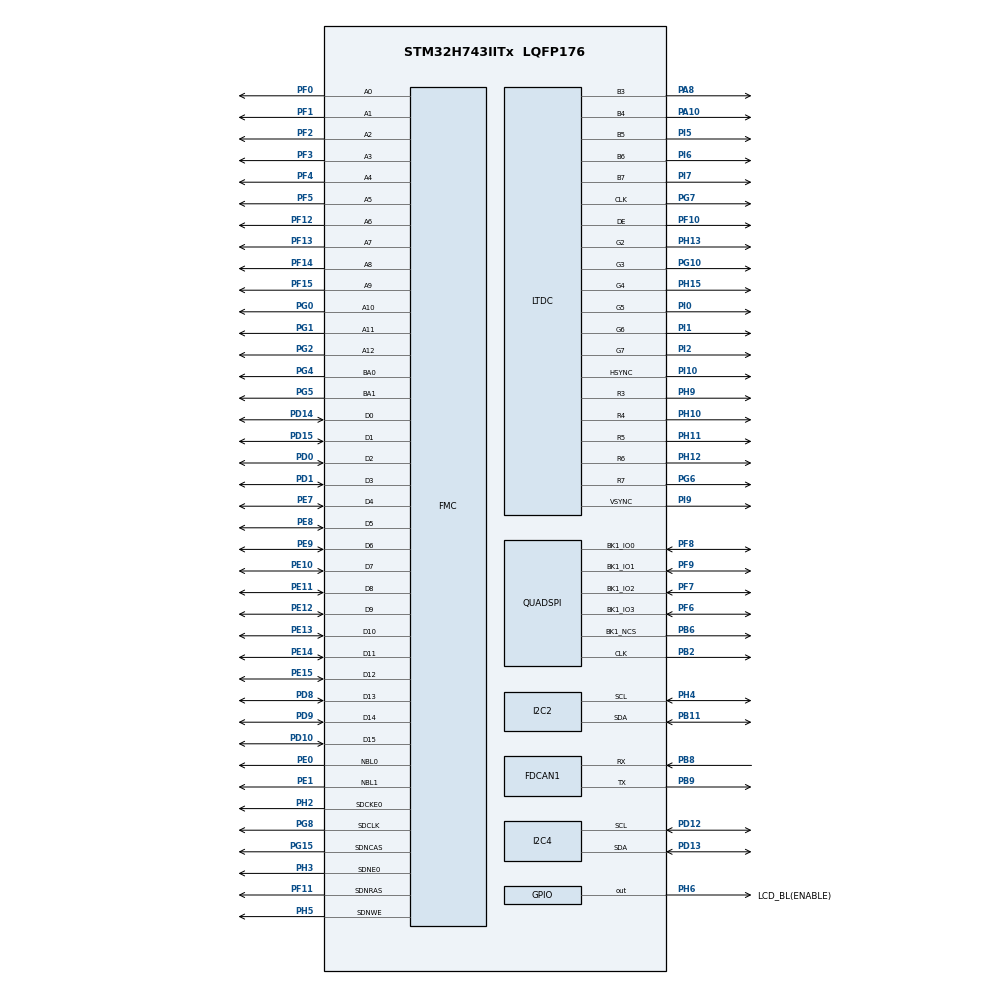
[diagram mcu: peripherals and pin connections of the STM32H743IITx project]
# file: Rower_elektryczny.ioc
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CORTEX_M7.default_mode_Activation=1
FDCAN1.AutoRetransmission=ENABLE
FDCAN1.CalculateBaudRateNominal=500000
FDCAN1.CalculateTimeBitNominal=2000
FDCAN1.CalculateTimeQuantumNominal=80.0
FDCAN1.ClockCalibrationCCU=DISABLE
FDCAN1.DataPrescaler=2
FDCAN1.DataSyncJumpWidth=12
FDCAN1.DataTimeSeg1=12
FDCAN1.DataTimeSeg2=7
FDCAN1.ExtFiltersNbr=5
FDCAN1.Mode=FDCAN_MODE_NORMAL
FDCAN1.NominalPrescaler=2
FDCAN1.NominalSyncJumpWidth=7
FDCAN1.NominalTimeSeg1=17
FDCAN1.NominalTimeSeg2=7
FDCAN1.RxFifo0ElmtsNbr=5
FDCAN1.StdFiltersNbr=5
FDCAN1.TxFifoQueueElmtsNbr=3
FMC.CASLatency1=FMC_SDRAM_CAS_LATENCY_3
FMC.ColumnBitsNumber1=FMC_SDRAM_COLUMN_BITS_NUM_9
FMC.ExitSelfRefreshDelay1=7
FMC.LoadToActiveDelay1=2
FMC.RCDDelay1=2
FMC.RPDelay1=2
FMC.RPDelay2=2
FMC.ReadPipeDelay1=FMC_SDRAM_RPIPE_DELAY_1
FMC.ReadPipeDelay2=FMC_SDRAM_RPIPE_DELAY_1
FMC.RowCycleDelay1=7
FMC.RowCycleDelay2=7
FMC.SDClockPeriod1=FMC_SDRAM_CLOCK_PERIOD_2
FMC.SDClockPeriod2=FMC_SDRAM_CLOCK_PERIOD_2
FMC.SelfRefreshTime1=4
FMC.WriteRecoveryTime1=3
I2C2.Timing=0x00000E14
I2C4.Timing=0x00000E14
LTDC.Alpha_L0=255
LTDC.Alpha_L1=255
LTDC.FBStartAdress_L0=0xc0000000
LTDC.ImageHeight_L0=600
LTDC.ImageWidth_L0=1024
LTDC.Layers=0
LTDC.PixelFormat_L0=LTDC_PIXEL_FORMAT_RGB565
LTDC.WindowX1_L0=1024
LTDC.WindowX1_L1=1024
LTDC.WindowY1_L0=600
LTDC.WindowY1_L1=600
Mcu.Family=STM32H7
Mcu.Name=STM32H743IITx
Mcu.Package=LQFP176
NVIC.FDCAN1_IT0_IRQn=true\:0\:0\:false\:false\:true\:true\:true\:true
NVIC.FDCAN1_IT1_IRQn=true\:0\:0\:false\:false\:true\:true\:true\:true
NVIC.FDCAN_CAL_IRQn=true\:0\:0\:false\:false\:true\:true\:true\:true
NVIC.FMC_IRQn=true\:0\:0\:false\:false\:true\:true\:true\:true
NVIC.PriorityGroup=NVIC_PRIORITYGROUP_4
PA10.Mode=RGB565
PA10.Signal=LTDC_B4
PA13\ (JTMS/SWDIO).Mode=Serial_Wire
PA13\ (JTMS/SWDIO).Signal=DEBUG_JTMS-SWDIO
PA14\ (JTCK/SWCLK).Mode=Serial_Wire
PA14\ (JTCK/SWCLK).Signal=DEBUG_JTCK-SWCLK
PA8.Mode=RGB565
PA8.Signal=LTDC_B3
PB11.Mode=I2C
PB11.Signal=I2C2_SDA
PB2.Mode=Single Bank 1
PB2.Signal=QUADSPI_CLK
PB3\ (JTDO/TRACESWO).Signal=SDMMC2_D2
PB6.Mode=Single Bank 1
PB6.Signal=QUADSPI_BK1_NCS
PB8.Mode=FDCAN_Activate
PB8.Signal=FDCAN1_RX
PB9.Mode=FDCAN_Activate
PB9.Signal=FDCAN1_TX
PC14-OSC32_IN\ (OSC32_IN).Mode=LSE-External-Oscillator
PC14-OSC32_IN\ (OSC32_IN).Signal=RCC_OSC32_IN
PC15-OSC32_OUT\ (OSC32_OUT).Mode=LSE-External-Oscillator
PC15-OSC32_OUT\ (OSC32_OUT).Signal=RCC_OSC32_OUT
PD0.Signal=FMC_D2_DA2
PD1.Signal=FMC_D3_DA3
PD10.Signal=FMC_D15_DA15
PD12.Mode=I2C
PD12.Signal=I2C4_SCL
PD13.Mode=I2C
PD13.Signal=I2C4_SDA
PD14.Signal=FMC_D0_DA0
PD15.Signal=FMC_D1_DA1
PD7.Signal=SDMMC2_CMD
PD8.Signal=FMC_D13_DA13
PD9.Signal=FMC_D14_DA14
PE0.Signal=FMC_NBL0
PE1.Signal=FMC_NBL1
PE10.Signal=FMC_D7_DA7
PE11.Signal=FMC_D8_DA8
PE12.Signal=FMC_D9_DA9
PE13.Signal=FMC_D10_DA10
PE14.Signal=FMC_D11_DA11
PE15.Signal=FMC_D12_DA12
PE7.Signal=FMC_D4_DA4
PE8.Signal=FMC_D5_DA5
PE9.Signal=FMC_D6_DA6
PF0.Signal=FMC_A0
PF1.Signal=FMC_A1
PF10.Mode=RGB565
PF10.Signal=LTDC_DE
PF11.Signal=FMC_SDNRAS
PF12.Signal=FMC_A6
PF13.Signal=FMC_A7
PF14.Signal=FMC_A8
PF15.Signal=FMC_A9
PF2.Signal=FMC_A2
PF3.Signal=FMC_A3
PF4.Signal=FMC_A4
PF5.Signal=FMC_A5
PF6.Mode=Single Bank 1
PF6.Signal=QUADSPI_BK1_IO3
PF7.Mode=Single Bank 1
PF7.Signal=QUADSPI_BK1_IO2
PF8.Mode=Single Bank 1
PF8.Signal=QUADSPI_BK1_IO0
PF9.Mode=Single Bank 1
PF9.Signal=QUADSPI_BK1_IO1
PG0.Signal=FMC_A10
PG1.Signal=FMC_A11
PG10.Mode=RGB565
PG10.Signal=LTDC_G3
PG15.Signal=FMC_SDNCAS
PG2.Signal=FMC_A12
PG4.Signal=FMC_A14_BA0
PG5.Signal=FMC_A15_BA1
PG6.Mode=RGB565
PG6.Signal=LTDC_R7
PG7.Mode=RGB565
PG7.Signal=LTDC_CLK
PG8.Signal=FMC_SDCLK
PH0-OSC_IN\ (PH0).Mode=HSE-External-Oscillator
PH0-OSC_IN\ (PH0).Signal=RCC_OSC_IN
PH1-OSC_OUT\ (PH1).Mode=HSE-External-Oscillator
PH1-OSC_OUT\ (PH1).Signal=RCC_OSC_OUT
PH10.Mode=RGB565
PH10.Signal=LTDC_R4
PH11.Mode=RGB565
PH11.Signal=LTDC_R5
PH12.Mode=RGB565
PH12.Signal=LTDC_R6
PH13.Mode=RGB565
PH13.Signal=LTDC_G2
PH15.Mode=RGB565
PH15.Signal=LTDC_G4
PH2.Mode=SdramChipSelect1_1
PH2.Signal=FMC_SDCKE0
PH3.Mode=SdramChipSelect1_1
PH3.Signal=FMC_SDNE0
PH4.Mode=I2C
PH4.Signal=I2C2_SCL
PH5.Signal=FMC_SDNWE
PH6.GPIO_Label=LCD_BL(ENABLE)
PH6.Signal=GPIO_Output
PH9.Mode=RGB565
PH9.Signal=LTDC_R3
PI0.Mode=RGB565
PI0.Signal=LTDC_G5
PI1.Mode=RGB565
PI1.Signal=LTDC_G6
PI10.Mode=RGB565
PI10.Signal=LTDC_HSYNC
PI2.Mode=RGB565
PI2.Signal=LTDC_G7
PI5.Mode=RGB565
PI5.Signal=LTDC_B5
PI6.Mode=RGB565
PI6.Signal=LTDC_B6
PI7.Mode=RGB565
PI7.Signal=LTDC_B7
PI9.Mode=RGB565
PI9.Signal=LTDC_VSYNC
ProjectManager.HeapSize=0x200
ProjectManager.StackSize=0x400
ProjectManager.TargetToolchain=STM32CubeIDE
RCC.ADCFreq_Value=129000000
RCC.APB1Freq_Value=64000000
RCC.APB2Freq_Value=64000000
RCC.APB3Freq_Value=64000000
RCC.APB4Freq_Value=64000000
RCC.CortexFreq_Value=64000000
RCC.DIVM1=4
RCC.DIVM3=1
RCC.DIVN1=10
RCC.DIVN3=4
RCC.DIVQ1=3
RCC.DIVR3=6
RCC.FDCANCLockSelection=RCC_FDCANCLKSOURCE_HSE
RCC.HCLKFreq_Value=64000000
RCC.I2C123CLockSelection=RCC_I2C123CLKSOURCE_CSI
RCC.I2C4CLockSelection=RCC_I2C4CLKSOURCE_CSI
RCC.PLL2FRACN=0
RCC.PLL3FRACN=0
RCC.PLLFRACN=0
RCC.SYSCLKFreq_VALUE=64000000
RCC.USBFreq_Value=53333333.333333336
SH.FMC_A0.0=FMC_A0,13b-sda1
SH.FMC_A1.0=FMC_A1,13b-sda1
SH.FMC_A10.0=FMC_A10,13b-sda1
SH.FMC_A11.0=FMC_A11,13b-sda1
SH.FMC_A12.0=FMC_A12,13b-sda1
SH.FMC_A14_BA0.0=FMC_BA0,FourSdramBanks1
SH.FMC_A15_BA1.0=FMC_BA1,FourSdramBanks1
SH.FMC_A2.0=FMC_A2,13b-sda1
SH.FMC_A3.0=FMC_A3,13b-sda1
SH.FMC_A4.0=FMC_A4,13b-sda1
SH.FMC_A5.0=FMC_A5,13b-sda1
SH.FMC_A6.0=FMC_A6,13b-sda1
SH.FMC_A7.0=FMC_A7,13b-sda1
SH.FMC_A8.0=FMC_A8,13b-sda1
SH.FMC_A9.0=FMC_A9,13b-sda1
SH.FMC_D0_DA0.0=FMC_D0,sd-16b-d1
SH.FMC_D10_DA10.0=FMC_D10,sd-16b-d1
SH.FMC_D11_DA11.0=FMC_D11,sd-16b-d1
SH.FMC_D12_DA12.0=FMC_D12,sd-16b-d1
SH.FMC_D13_DA13.0=FMC_D13,sd-16b-d1
SH.FMC_D14_DA14.0=FMC_D14,sd-16b-d1
SH.FMC_D15_DA15.0=FMC_D15,sd-16b-d1
SH.FMC_D1_DA1.0=FMC_D1,sd-16b-d1
SH.FMC_D2_DA2.0=FMC_D2,sd-16b-d1
SH.FMC_D3_DA3.0=FMC_D3,sd-16b-d1
SH.FMC_D4_DA4.0=FMC_D4,sd-16b-d1
SH.FMC_D5_DA5.0=FMC_D5,sd-16b-d1
SH.FMC_D6_DA6.0=FMC_D6,sd-16b-d1
SH.FMC_D7_DA7.0=FMC_D7,sd-16b-d1
SH.FMC_D8_DA8.0=FMC_D8,sd-16b-d1
SH.FMC_D9_DA9.0=FMC_D9,sd-16b-d1
SH.FMC_NBL0.0=FMC_NBL0,Sd2ByteEnable1
SH.FMC_NBL1.0=FMC_NBL1,Sd2ByteEnable1
SH.FMC_SDCLK.0=FMC_SDCLK,13b-sda1
SH.FMC_SDNCAS.0=FMC_SDNCAS,13b-sda1
SH.FMC_SDNRAS.0=FMC_SDNRAS,13b-sda1
SH.FMC_SDNWE.0=FMC_SDNWE,13b-sda1
VP_CRC_VS_CRC.Mode=CRC_Activate
VP_DMA2D_VS_DMA2D.Mode=DMA2D_Activate
VP_MEMORYMAP_VS_MEMORYMAP.Mode=CurAppReg
VP_RCC_LSE.Mode=CRS SYNC Source LSE
board=custom

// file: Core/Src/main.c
/* USER CODE BEGIN Header */
/**
  ******************************************************************************
  * @file           : main.c
  * @brief          : Main program body
  ******************************************************************************
  * @attention
  *
  * Copyright (c) 2025 STMicroelectronics.
  * All rights reserved.
  *
  * This software is licensed under terms that can be found in the LICENSE file
  * in the root directory of this software component.
  * If no LICENSE file comes with this software, it is provided AS-IS.
  *
  ******************************************************************************
  */
/* USER CODE END Header */
#include "main.h"
#include "crc.h"
#include "dma2d.h"
#include "fdcan.h"
#include "i2c.h"
#include "ltdc.h"
#include "memorymap.h"
#include "quadspi.h"
#include "gpio.h"
#include "fmc.h"

/* USER CODE BEGIN PV */
FDCAN_RxHeaderTypeDef RxHeader;
uint8_t RxData[8]; // Bufor na dane odebrane z VESC
uint8_t TxData[8]; // Bufor na dane do wysłania
// --- 1. DEFINICJA STRUKTURY DLA WSZYSTKICH STATUSÓW ---
FDCAN_TxHeaderTypeDef TxHeader;
typedef struct {
    // === STATUS 1 (Komenda 0x09) ===
    volatile int32_t rpm;           // Prędkość obrotowa (ERPM)
    volatile float current_motor;   // Prąd na silniku (A)
    volatile float duty_cycle;      // Wypełnienie (0.00 - 1.00)

    // === STATUS 2 (Komenda 0x0E) ===
    volatile float amp_hours;       // Zużyte amperogodziny (Ah)
    volatile float amp_hours_chg;   // Odzyskane amperogodziny (ładowanie)

    // === STATUS 3 (Komenda 0x0F) ===
    volatile float watt_hours;      // Zużyte watogodziny (Wh)
    volatile float watt_hours_chg;  // Odzyskane watogodziny (ładowanie)

    // === STATUS 4 (Komenda 0x10) ===
    volatile float temp_fet;        // Temperatura MOSFET-ów (st. C)
    volatile float temp_motor;      // Temperatura Silnika (st. C)
    volatile float current_in;      // Prąd pobierany z baterii (A)
    volatile float pid_pos;         // Pozycja PID (kąt 0-360)

    // === STATUS 5 (Komenda 0x1B) ===
    volatile int32_t tacho_value;   // Licznik obrotów (przebieg)
    volatile float v_in;            // Napięcie baterii (V)

} VescData_t;

// --- 2. INSTANCJE DLA SILNIKÓW ---
// Ustawiamy ID Twoich VESC-ów
#define VESC_ID_L  1   // Lewy
#define VESC_ID_M  2   // Środkowy
#define VESC_ID_R  3   // Prawy (przykładowo)

VescData_t vescL; // Zmienna dla lewego
VescData_t vescM; // Zmienna dla środkowego
VescData_t vescR; // Zmienna dla prawego

// --- MPU6050 DEFINICJE ---
#define MPU6050_ADDR 0xD0 // Adres urządzenia (0x68 << 1)
#define SMPLRT_DIV_REG 0x19
#define GYRO_CONFIG_REG 0x1B
#define ACCEL_CONFIG_REG 0x1C
#define ACCEL_XOUT_H_REG 0x3B
#define TEMP_OUT_H_REG 0x41
#define GYRO_XOUT_H_REG 0x43
#define PWR_MGMT_1_REG 0x6B
#define WHO_AM_I_REG 0x75

// Struktura przechowująca dane z czujnika
typedef struct {
    int16_t Accel_X_RAW;
    int16_t Accel_Y_RAW;
    int16_t Accel_Z_RAW;
    double Ax; // Przyspieszenie w g
    double Ay;
    double Az;

    int16_t Gyro_X_RAW;
    int16_t Gyro_Y_RAW;
    int16_t Gyro_Z_RAW;
    double Gx; // Prędkość kątowa w deg/s
    double Gy;
    double Gz;

    float Temperature;
} MPU6050_t;

MPU6050_t MPU6050; // Globalna instancja struktury

/* USER CODE END PV */

void SystemClock_Config(void);
static void MPU_Config(void);

/* USER CODE BEGIN PFP */
void VESC_SetDuty(uint8_t controller_id, float dutyCycle);
void VESC_SetAllDuty(float duty_Left, float duty_Right, float duty_Gen);

uint8_t MPU6050_Init(I2C_HandleTypeDef *I2Cx);
void MPU6050_Read_All(I2C_HandleTypeDef *I2Cx, MPU6050_t *DataStruct);
/* USER CODE END PFP */

int main(void)
{

  /* MPU Configuration--------------------------------------------------------*/
  MPU_Config();

  /* MCU Configuration--------------------------------------------------------*/

  /* Reset of all peripherals, Initializes the Flash interface and the Systick. */
  HAL_Init();

  /* Configure the system clock */
  SystemClock_Config();

  /* Initialize all configured peripherals */
  MX_GPIO_Init();
  MX_FMC_Init();
  MX_QUADSPI_Init();
  MX_LTDC_Init();
  MX_DMA2D_Init();
  MX_FDCAN1_Init();
  MX_I2C4_Init();
  MX_I2C2_Init();
  MX_CRC_Init();
  /* USER CODE BEGIN 2 */
  // 1. Konfiguracja Filtra - akceptujemy WSZYSTKO (tryb otwarty dla testów)
    // VESC wysyła ramki z ID rozszerzonym (29-bit).
    FDCAN_FilterTypeDef sFilterConfig;

    sFilterConfig.IdType = FDCAN_EXTENDED_ID;
    sFilterConfig.FilterIndex = 0;
    sFilterConfig.FilterType = FDCAN_FILTER_MASK;
    sFilterConfig.FilterConfig = FDCAN_FILTER_TO_RXFIFO0;
    sFilterConfig.FilterID1 = 0;     // Akceptuj wszystko
    sFilterConfig.FilterID2 = 0;     // Maska 0 = ignoruj bity ID (bierz wszystko jak leci)

    if (HAL_FDCAN_ConfigFilter(&hfdcan1, &sFilterConfig) != HAL_OK)
    {
      Error_Handler();
    }

    // 2. Start modułu FDCAN
    if (HAL_FDCAN_Start(&hfdcan1) != HAL_OK)
    {
      Error_Handler();
    }

    // 3. Włączenie przerwań (chcemy wiedzieć, kiedy przyjdzie nowa wiadomość)
    if (HAL_FDCAN_ActivateNotification(&hfdcan1, FDCAN_IT_RX_FIFO0_NEW_MESSAGE, 0) != HAL_OK)
    {
      Error_Handler();
    }
    if (MPU6050_Init(&hi2c2) == 0) {
          // Opcjonalnie: mignij diodą, że MPU OK
      }
  /* USER CODE END 2 */

  /* Infinite loop */
  /* USER CODE BEGIN WHILE */
    // Zmienna do filtra (musi być static, żeby pamiętała wartość z poprzedniego obiegu)
      static float current_filtered = 0.0f;

      // Konfiguracja Twojej krzywej
      const float MAX_GEN_RPM = 10000.0f; // Przy jakich obrotach chcesz miec PEŁNĄ MOC (zwiększ jeśli 8000 to za mało)
      const float MAX_CURRENT = 20.0f;    // Maksymalny prąd w Amperach
      const float RAMP_FACTOR = 0.05f;    // Jak szybko prąd ma gonić cel (0.01 = bardzo wolno/płynnie, 0.1 = szybko)

  while (1)
  {
    /* USER CODE END WHILE */

    /* USER CODE BEGIN 3 */
	  MPU6050_Read_All(&hi2c2, &MPU6050);
	  // 1. Pobierz obroty
	      int32_t rpm_raw = vescM.rpm;
	      if (rpm_raw < 0) rpm_raw = 0; // Zabezpieczenie przed ujemnymi

	      // 2. Martwa strefa (np. do 200 erpm nic nie rób, żeby silnik nie buczał na postoju)
	      if (rpm_raw < 200) rpm_raw = 0;

	      // --- MAGIA MATEMATYKI (Krzywa Kwadratowa) ---

	      // A. Obliczamy w jakim % drogi do maksa jesteśmy (0.0 do 1.0)
	      float throttle_pos = (float)rpm_raw / MAX_GEN_RPM;
	      if (throttle_pos > 1.0f) throttle_pos = 1.0f; // Nie przekraczaj 100%

	      // B. Podnosimy do kwadratu -> To daje łagodny start!
	      // Przykład:
	      // Liniowo: 50% RPM = 50% Prądu
	      // Kwadratowo: 0.5 * 0.5 = 0.25 (czyli przy połowie obrotów masz tylko 25% mocy!)
	      float current_target = throttle_pos * throttle_pos * MAX_CURRENT;

	      // --- FILTROWANIE (RAMPING) ---
	      // To realizuje Twoją prośbę o "mniejsze przyrosty".
	      // Prąd nie skacze od razu do celu, tylko zbliża się o 5% różnicy w każdym kroku pętli.
	      current_filtered = (current_filtered * (1.0f - RAMP_FACTOR)) + (current_target * RAMP_FACTOR);

	      // Zabezpieczenie "na wszelki wypadek"
	      if (current_filtered < 0.1f) current_filtered = 0.0f; // Zeruj małe śmieci

	      // 3. Wyślij wygładzony, "miękki" prąd na silniki
	      VESC_SetCurrent(VESC_ID_L, current_filtered);

	      // Krótkie opóźnienie dla stabilności CAN (ważne przy 3 VESC)
	      HAL_Delay(1);

	      VESC_SetCurrent(VESC_ID_R, current_filtered);

	      // Częstotliwość pętli (ok 50Hz)
	      HAL_Delay(20);
  }
  /* USER CODE END 3 */
}

void SystemClock_Config(void)
{
  RCC_OscInitTypeDef RCC_OscInitStruct = {0};
  RCC_ClkInitTypeDef RCC_ClkInitStruct = {0};
  RCC_CRSInitTypeDef RCC_CRSInitStruct = {0};

  /** Supply configuration update enable
  */
  HAL_PWREx_ConfigSupply(PWR_LDO_SUPPLY);

  /** Configure the main internal regulator output voltage
  */
  __HAL_PWR_VOLTAGESCALING_CONFIG(PWR_REGULATOR_VOLTAGE_SCALE3);

  while(!__HAL_PWR_GET_FLAG(PWR_FLAG_VOSRDY)) {}

  /** Configure LSE Drive Capability
  */
  HAL_PWR_EnableBkUpAccess();
  __HAL_RCC_LSEDRIVE_CONFIG(RCC_LSEDRIVE_LOW);

  /** Macro to configure the PLL clock source
  */
  __HAL_RCC_PLL_PLLSOURCE_CONFIG(RCC_PLLSOURCE_HSI);

  /** Initializes the RCC Oscillators according to the specified parameters
  * in the RCC_OscInitTypeDef structure.
  */
  RCC_OscInitStruct.OscillatorType = RCC_OSCILLATORTYPE_HSI48|RCC_OSCILLATORTYPE_CSI
                              |RCC_OSCILLATORTYPE_HSI|RCC_OSCILLATORTYPE_HSE
                              |RCC_OSCILLATORTYPE_LSE;
  RCC_OscInitStruct.HSEState = RCC_HSE_ON;
  RCC_OscInitStruct.LSEState = RCC_LSE_ON;
  RCC_OscInitStruct.HSIState = RCC_HSI_DIV1;
  RCC_OscInitStruct.HSICalibrationValue = RCC_HSICALIBRATION_DEFAULT;
  RCC_OscInitStruct.HSI48State = RCC_HSI48_ON;
  RCC_OscInitStruct.CSIState = RCC_CSI_ON;
  RCC_OscInitStruct.CSICalibrationValue = RCC_CSICALIBRATION_DEFAULT;
  RCC_OscInitStruct.PLL.PLLState = RCC_PLL_NONE;
  if (HAL_RCC_OscConfig(&RCC_OscInitStruct) != HAL_OK)
  {
    Error_Handler();
  }

  /** Initializes the CPU, AHB and APB buses clocks
  */
  RCC_ClkInitStruct.ClockType = RCC_CLOCKTYPE_HCLK|RCC_CLOCKTYPE_SYSCLK
                              |RCC_CLOCKTYPE_PCLK1|RCC_CLOCKTYPE_PCLK2
                              |RCC_CLOCKTYPE_D3PCLK1|RCC_CLOCKTYPE_D1PCLK1;
  RCC_ClkInitStruct.SYSCLKSource = RCC_SYSCLKSOURCE_HSI;
  RCC_ClkInitStruct.SYSCLKDivider = RCC_SYSCLK_DIV1;
  RCC_ClkInitStruct.AHBCLKDivider = RCC_HCLK_DIV1;
  RCC_ClkInitStruct.APB3CLKDivider = RCC_APB3_DIV1;
  RCC_ClkInitStruct.APB1CLKDivider = RCC_APB1_DIV1;
  RCC_ClkInitStruct.APB2CLKDivider = RCC_APB2_DIV1;
  RCC_ClkInitStruct.APB4CLKDivider = RCC_APB4_DIV1;

  if (HAL_RCC_ClockConfig(&RCC_ClkInitStruct, FLASH_LATENCY_1) != HAL_OK)
  {
    Error_Handler();
  }

  /** Enable the SYSCFG APB clock
  */
  __HAL_RCC_CRS_CLK_ENABLE();

  /** Configures CRS
  */
  RCC_CRSInitStruct.Prescaler = RCC_CRS_SYNC_DIV1;
  RCC_CRSInitStruct.Source = RCC_CRS_SYNC_SOURCE_LSE;
  RCC_CRSInitStruct.Polarity = RCC_CRS_SYNC_POLARITY_RISING;
  RCC_CRSInitStruct.ReloadValue = __HAL_RCC_CRS_RELOADVALUE_CALCULATE(48000000,32768);
  RCC_CRSInitStruct.ErrorLimitValue = 34;
  RCC_CRSInitStruct.HSI48CalibrationValue = 32;

  HAL_RCCEx_CRSConfig(&RCC_CRSInitStruct);
}

/* USER CODE BEGIN 4 */
void HAL_FDCAN_RxFifo0Callback(FDCAN_HandleTypeDef *hfdcan, uint32_t RxFifo0ITs)
{
    // Czy przyszła nowa wiadomość?
    if ((RxFifo0ITs & FDCAN_IT_RX_FIFO0_NEW_MESSAGE) != 0)
    {
        // Pobierz wiadomość
        if (HAL_FDCAN_GetRxMessage(hfdcan, FDCAN_RX_FIFO0, &RxHeader, RxData) == HAL_OK)
        {
            // 1. Rozpoznanie KTO wysłał (ID VESC)
            uint8_t id_nadawcy = (RxHeader.Identifier & 0xFF);

            // 2. Rozpoznanie CO wysłał (Komenda)
            uint8_t komenda = (RxHeader.Identifier >> 8) & 0xFF;

            // 3. Wybór odpowiedniej struktury (Wskaźnik)
            VescData_t *target = NULL;

            if      (id_nadawcy == VESC_ID_M) target = &vescM; // Środkowy
            else if (id_nadawcy == VESC_ID_L) target = &vescL; // Lewy
            else if (id_nadawcy == VESC_ID_R) target = &vescR; // Prawy

            // Jeśli znaleźliśmy pasujący silnik, dekodujemy dane
            if (target != NULL)
            {
                switch (komenda)
                {
                    // --- STATUS 1: RPM, Prąd Silnika, Duty ---
                    case 0x09:
                        target->rpm = (int32_t)((RxData[0] << 24) | (RxData[1] << 16) | (RxData[2] << 8) | RxData[3]);
                        target->current_motor = (float)((int16_t)((RxData[4] << 8) | RxData[5])) / 10.0f;
                        target->duty_cycle = (float)((int16_t)((RxData[6] << 8) | RxData[7])) / 1000.0f;
                        break;

                        // --- STATUS 2: Ah zużyte, Ah odzyskane ---
                        case 0x0E:
                            target->amp_hours = (float)((int32_t)((RxData[0] << 24) | (RxData[1] << 16) | (RxData[2] << 8) | RxData[3])) / 10000.0f;
                            // POPRAWKA PONIŻEJ: 24, 16, 8, 0
                            target->amp_hours_chg = (float)((int32_t)((RxData[4] << 24) | (RxData[5] << 16) | (RxData[6] << 8) | RxData[7])) / 10000.0f;
                            break;

                        // --- STATUS 3: Wh zużyte, Wh odzyskane ---
                        case 0x0F:
                             target->watt_hours = (float)((int32_t)((RxData[0] << 24) | (RxData[1] << 16) | (RxData[2] << 8) | RxData[3])) / 10000.0f;
                             // POPRAWKA PONIŻEJ: 24, 16, 8, 0
                             target->watt_hours_chg = (float)((int32_t)((RxData[4] << 24) | (RxData[5] << 16) | (RxData[6] << 8) | RxData[7])) / 10000.0f;
                            break;

                    // --- STATUS 4: Temperatury, Prąd Baterii ---
                    case 0x10:
                        target->temp_fet = (float)((int16_t)((RxData[0] << 8) | RxData[1])) / 10.0f;
                        target->temp_motor = (float)((int16_t)((RxData[2] << 8) | RxData[3])) / 10.0f;
                        target->current_in = (float)((int16_t)((RxData[4] << 8) | RxData[5])) / 10.0f;
                        target->pid_pos = (float)((int16_t)((RxData[6] << 8) | RxData[7])) / 50.0f;
                        break;

                    // --- STATUS 5: Tachometr, Napięcie Baterii ---
                    case 0x1B:
                        target->tacho_value = (int32_t)((RxData[0] << 24) | (RxData[1] << 16) | (RxData[2] << 8) | RxData[3]);
                        target->v_in = (float)((int16_t)((RxData[4] << 8) | RxData[5])) / 10.0f;
                        break;

                    default:
                        break;
                }
            }
        }
        // Ponowne włączenie nasłuchiwania
        HAL_FDCAN_ActivateNotification(hfdcan, FDCAN_IT_RX_FIFO0_NEW_MESSAGE, 0);
    }
}

// --- Funkcja ustawiania PRĄDU (Momentu) ---
// Komenda 0x01 w VESC to Set Current
void VESC_SetCurrent(uint8_t controller_id, float current_amps)
{
    // 1. Zabezpieczenie przed ujemnym prądem (chyba że chcesz hamować/wsteczny)
    // Zakładamy, że rower jedzie tylko do przodu.
    if (current_amps < 0.0f) current_amps = 0.0f;

    // 2. Zabezpieczenie maksymalnego prądu (bezpiecznik programowy)
    // Z tabelki wynika max 20A, ale dajmy bezpiecznik np. 30A
    if (current_amps > 30.0f) current_amps = 30.0f;

    // 3. Skalowanie: VESC oczekuje prądu * 1000 (miliampery)
    int32_t send_val = (int32_t)(current_amps * 1000.0f);

    FDCAN_TxHeaderTypeDef TxHeader;
    uint8_t TxData[4];

    // Budowa ID ramki: [KOMENDA 0x01] [ID_STEROWNIKA]
    TxHeader.Identifier = (uint32_t)controller_id | ((uint32_t)0x01 << 8);

    // Konfiguracja FDCAN (identyczna jak w działającym SetDuty)
    TxHeader.IdType = FDCAN_EXTENDED_ID;
    TxHeader.TxFrameType = FDCAN_DATA_FRAME;
    TxHeader.DataLength = FDCAN_DLC_BYTES_4;
    TxHeader.ErrorStateIndicator = FDCAN_ESI_ACTIVE;
    TxHeader.BitRateSwitch = FDCAN_BRS_OFF;
    TxHeader.FDFormat = FDCAN_CLASSIC_CAN;
    TxHeader.TxEventFifoControl = FDCAN_NO_TX_EVENTS;
    TxHeader.MessageMarker = 0;

    // Pakowanie danych (Big Endian)
    TxData[0] = (uint8_t)((send_val >> 24) & 0xFF);
    TxData[1] = (uint8_t)((send_val >> 16) & 0xFF);
    TxData[2] = (uint8_t)((send_val >> 8)  & 0xFF);
    TxData[3] = (uint8_t)(send_val & 0xFF);

    // Wysłanie do kolejki
    if (HAL_FDCAN_GetTxFifoFreeLevel(&hfdcan1) > 0)
    {
        HAL_FDCAN_AddMessageToTxFifoQ(&hfdcan1, &TxHeader, TxData);
    }
}

/* USER CODE END 4 */

 /* MPU Configuration */

void MPU_Config(void)
{
  MPU_Region_InitTypeDef MPU_InitStruct = {0};

  /* Disables the MPU */
  HAL_MPU_Disable();

  /** Initializes and configures the Region and the memory to be protected
  */
  MPU_InitStruct.Enable = MPU_REGION_ENABLE;
  MPU_InitStruct.Number = MPU_REGION_NUMBER0;
  MPU_InitStruct.BaseAddress = 0x0;
  MPU_InitStruct.Size = MPU_REGION_SIZE_4GB;
  MPU_InitStruct.SubRegionDisable = 0x87;
  MPU_InitStruct.TypeExtField = MPU_TEX_LEVEL0;
  MPU_InitStruct.AccessPermission = MPU_REGION_NO_ACCESS;
  MPU_InitStruct.DisableExec = MPU_INSTRUCTION_ACCESS_DISABLE;
  MPU_InitStruct.IsShareable = MPU_ACCESS_SHAREABLE;
  MPU_InitStruct.IsCacheable = MPU_ACCESS_NOT_CACHEABLE;
  MPU_InitStruct.IsBufferable = MPU_ACCESS_NOT_BUFFERABLE;

  HAL_MPU_ConfigRegion(&MPU_InitStruct);
  /* Enables the MPU */
  HAL_MPU_Enable(MPU_PRIVILEGED_DEFAULT);

}

void Error_Handler(void)
{
  __disable_irq();
  while (1)
  {
  }
}
